# PIC32MK1024MCF064 device description
Architecture: MIPS; Family: PIC32MK; Series: PIC32MK
Registers are 32-bit, read-write, no defined reset value unless marked. A register's access mark holds for its fields unless they carry their own. Offsets are from the block's base; [hi:lo] are bit positions; lines under a group give offsets from that group; {n}, {i} and the like mark numbered series; 'fields as' and 'values as' point back to an identical list.

## RTCC
Instances: RTCC 0x1f8c0000 in periph_pb6_std
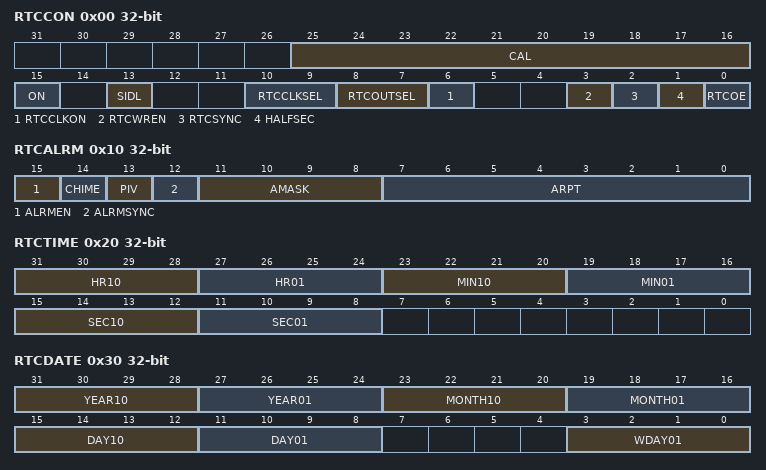
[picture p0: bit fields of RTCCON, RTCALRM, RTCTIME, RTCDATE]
0x00 RTCCON — Real-Time Clock and Calendar Control Register
  [25:16] CAL — Real-Time Clock Drift Calibration bits
    0x1ff=Maximum positive adjustment; 1=Minimum positive adjustment; 0=No adjustment; 0x3ff=Minimum negative adjustment; 0x200=Minimum negative adjustment
  [15] ON — RTCC On bit
    1=RTCC module is enabled; 0=RTCC module is disabled
  [13] SIDL — Stop in Idle Mode bit
    1=Disables RTCC operation when CPU enters Idle mode; 0=Continue normal operation when CPU enters Idle mode
  [10:9] RTCCLKSEL — RTCC Clock Select bits
    1=RTCC uses the external 32.768 kHz Secondary Oscillator (SOSC); 0=RTCC uses the internal 32 kHz oscillator (LPRC)
  [8:7] RTCOUTSEL — RTCC Output Data Select bits
    2=RTCC Clock is presented on the RTCC pin; 1=Seconds Clock is presented on the RTCC pin; 0=Alarm Pulse is presented on the RTCC pin when the alarm interrupt is triggered
  [6] RTCCLKON — RTCC Clock Enable Status bit
    1=RTCC Clock is actively running; 0=RTCC Clock is not running
  [3] RTCWREN — Real-Time Clock Value Registers Write Enable bit
    1=Real-Time Clock Value registers can be written to by the user; 0=Real-Time Clock Value registers are locked out from being written to by the user
  [2] RTCSYNC — Real-Time Clock Value Registers Read Synchronization bit
    1=Real-time clock value registers can change while reading (due to a rollover ripple that results in an invalid data read). If the register is read twice and results in the same data; 0=Real-time clock value registers can be read without concern about a rollover ripple
  [1] HALFSEC — Half-Second Status bit
    1=Second half period of a second; 0=First half period of a second
  [0] RTCOE — RTCC Output Enable bit
    1=RTCC output is enabled; 0=RTCC output is not enabled
0x10 RTCALRM — Real-Time Clock ALARM Control Register
  [15] ALRMEN — Alarm Enable bit
    1=Alarm is enabled; 0=Alarm is disabled
  [14] CHIME — Chime Enable bit
    1=Chime is enabled ARPT is allowed to rollover from 0x00 to 0xFF; 0=Chime is disabled ARPT stops once it reaches 0x00
  [13] PIV — Alarm Pulse Initial Value bit
    0=low initial value of the Alarm Pulse (When ALRMEN = 0); 1=high initial value of the Alarm Pulse (When ALRMEN = 0)
  [12] ALRMSYNC — Alarm Sync bit
    1=ARPT and ALRMEN may change as a result of a half second rollover during a read. The ARPT must be read repeatedly until the same value is read twice. This must be done since multiple bits may be changing.; 0=ARPT and ALRMEN can be read without concerns of rollover because the prescaler is more than 32 real-time clocks away from a half-second rollover
  [11:8] AMASK — Alarm Mask Configuration bits
    0=Every half-second; 1=Every second; 2=Every 10 seconds; 3=Every minute; 4=Every 10 minutes; 5=Every hour; 6=Once a day; 7=Once a week; 8=Once a month; 9=Once a year (except when configured for February 29
  [7:0] ARPT — Alarm Repeat Counter Value bits
    255=Alarm will trigger 256 times; 254=Alarm will trigger 255 times; 1=Alarm will trigger two times; 0=Alarm will trigger one time
0x20 RTCTIME — Real-Time Clock Time Value Register
  [31:28] HR10, [27:24] HR01, [23:20] MIN10, [19:16] MIN01, [15:12] SEC10, [11:8] SEC01
0x30 RTCDATE — Real-Time Clock Date Value Register
  [31:28] YEAR10, [27:24] YEAR01, [23:20] MONTH10, [19:16] MONTH01, [15:12] DAY10, [11:8] DAY01, [3:0] WDAY01
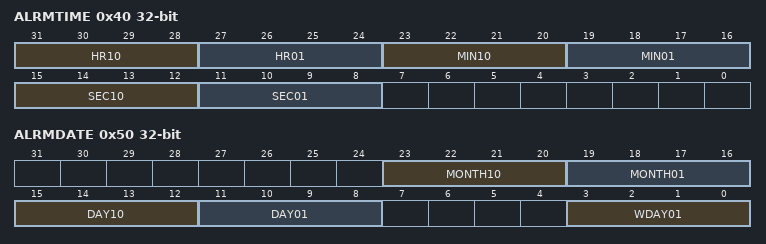
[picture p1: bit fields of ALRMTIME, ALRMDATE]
0x40 ALRMTIME — Alarm Time Value Register
  fields as RTCTIME
0x50 ALRMDATE — Alarm Date Value Register
  [23:20] MONTH10, [19:16] MONTH01, [15:12] DAY10, [11:8] DAY01, [3:0] WDAY01

## SB
Instances: SB 0x1f8f0510 in periph_ssx
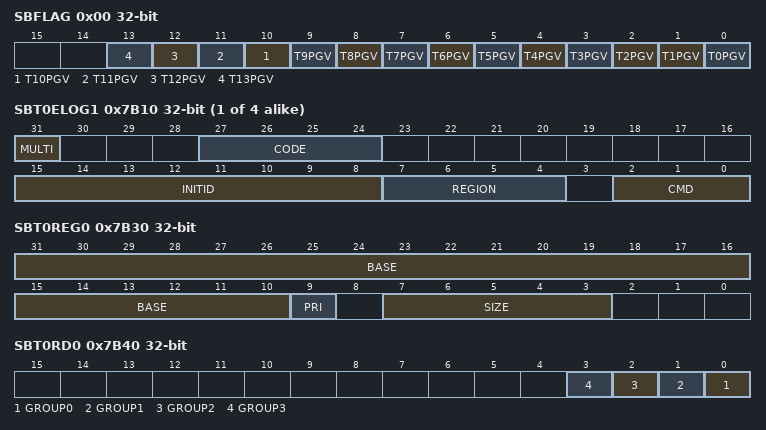
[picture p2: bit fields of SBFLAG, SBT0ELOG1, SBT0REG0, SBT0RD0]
0x00 SBFLAG ro — System Bus Status Flag Register
  [all] fields
    1=Target is reporting a Permission Group (PG) violation; 0=Target is not reporting a PG violation
  [n] T{n}PGV (n=2..13) — Target {n} Permission Group Violation Status bits
  [1] T1PGV — Target 1Permission Group Violation Status bits
  [0] T0PGV — Target 0 Permission Group Violation Status bits
{0x7B10+0x400*i} SBT{i}ELOG1 ro (i=0..3) — System Bus Target 'x' Error Log Register 1
  [31] MULTI — Multiple Permission Violations Status bit
    1=Multiple errors have been detected; 0=No multiple errors have been detected
  [27:24] CODE — Error Code bits
    3=Permission violation; 0=No error
  [15:8] INITID — Initiator ID of Requester bits
    14=Crypto Engine; 13=Flash Controller; 12=SQI1; 11=CAN2; 10=CAN1; 9=Ethernet Write; 8=Ethernet Read; 7=USB; 6=DMA Write (DMAPRI (CFGCON) = 1); 5=DMA Write (DMAPRI (CFGCON) = 0); 4=DMA Read (DMAPRI (CFGCON) = 1); 3=DMA Read (DMAPRI (CFGCON) = 0); 2=CPU (CPUPRI (CFGCON) = 1); 1=CPU (CPUPRI (CFGCON) = 0)
  [7:4] REGION — Requested Region Number bits
    1111 - 0000=Targets region that reported a permission group violation
  [2:0] CMD — Transaction Command of the Requester bits
    5=Write (a non-posted write); 3=Read (a locked read caused by a Read-Modify-Write transaction); 2=Read; 1=Write; 0=Idle
{0x7B14+0x400*i} SBT{i}ELOG2 ro (i=0..3) — System Bus Target 'x' Error Log Register 2
  [1:0] GROUP — Requested Permissions Group bits
    {v}=Group {v} (v=0..3)
{0x7B18+0x400*i} SBT{i}ECON (i=0..3) — System Bus Target 'x' Error Control Register
  [24] ERRP — Error Control bit
    1=Report protection group violation errors; 0=Do not report protection group violation errors
{0x7B20+0x400*i} SBT{i}ECLRS ro (i=0..3) — System Bus Target 'x' Single Error Clear Register
  [0] CLEAR
{0x7B28+0x400*i} SBT{i}ECLRM ro (i=0..3) — System Bus Target 'x' Multiple Error Clear Register
  [0] CLEAR
0x7B30 SBT0REG0
  [31:10] BASE
  [9] PRI — Region Priority Level bit
    1=Level 2; 0=Level 1
  [7:3] SIZE — Region Size bits
    0=Region is not present; 1=Region is 1024 bytes; 2=Region is 2048 bytes; 3=Region is 4096 bytes
0x7B40 SBT0RD0
  [n] GROUP{n} (n=0..3) — Group{n} Read Permissions bits
    1=Privilege Group {n} has read permission; 0=Privilege Group {n} does not have read permission
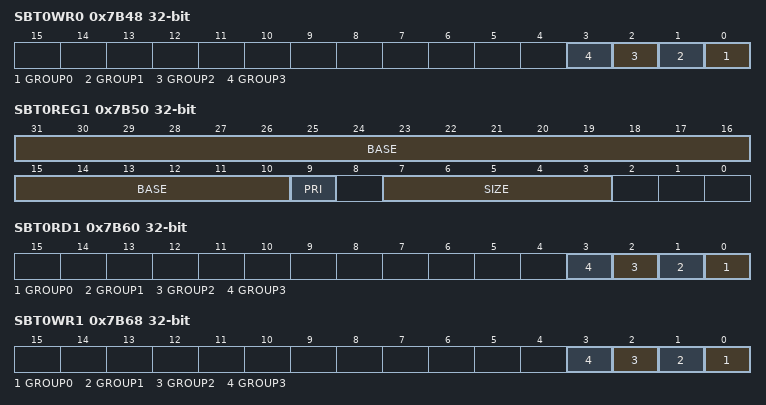
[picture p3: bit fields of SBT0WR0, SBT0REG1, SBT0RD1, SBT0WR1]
0x7B48 SBT0WR0
  [n] GROUP{n} (n=0..3) — Group {n} Write Permissions bits
    1=Privilege Group {n} has write permission; 0=Privilege Group {n} does not have write permission
0x7B50 SBT0REG1
  fields as SBT0REG0
0x7B60 SBT0RD1
  fields as SBT0RD0
0x7B68 SBT0WR1
  fields as SBT0WR0
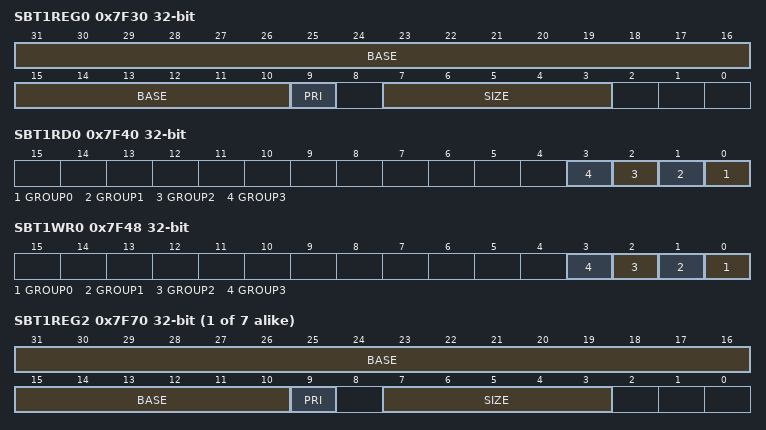
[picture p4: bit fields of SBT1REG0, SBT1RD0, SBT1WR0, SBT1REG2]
0x7F30 SBT1REG0
  fields as SBT0REG0
0x7F40 SBT1RD0
  fields as SBT0RD0
0x7F48 SBT1WR0
  fields as SBT0WR0
{0x7F30+0x20*i} SBT1REG{i} (i=2..8)
  fields as SBT0REG0
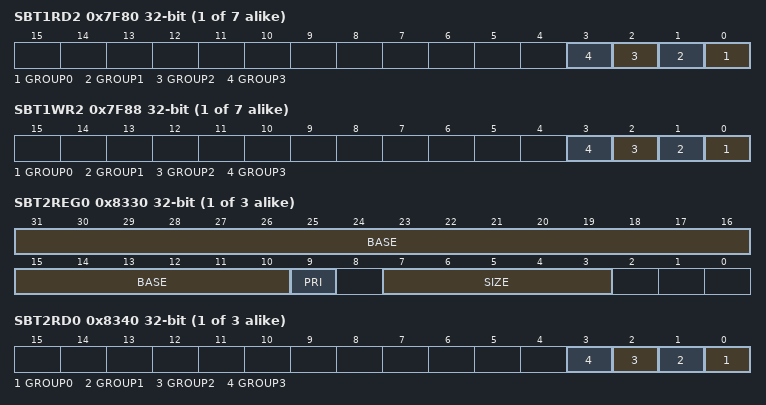
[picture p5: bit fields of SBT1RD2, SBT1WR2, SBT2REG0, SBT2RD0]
{0x7F40+0x20*i} SBT1RD{i} (i=2..8)
  fields as SBT0RD0
{0x7F48+0x20*i} SBT1WR{i} (i=2..8)
  fields as SBT0WR0
{0x8330+0x20*i} SBT2REG{i} (i=0..2)
  fields as SBT0REG0
{0x8340+0x20*i} SBT2RD{i} (i=0..2)
  fields as SBT0RD0
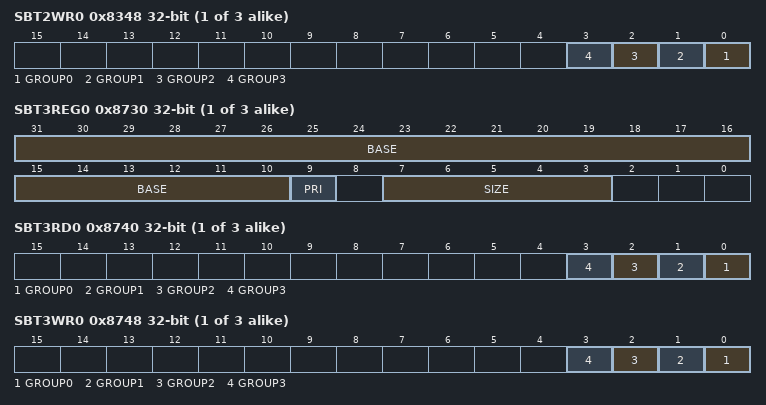
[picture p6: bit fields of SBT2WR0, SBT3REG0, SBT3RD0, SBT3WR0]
{0x8348+0x20*i} SBT2WR{i} (i=0..2)
  fields as SBT0WR0
{0x8730+0x20*i} SBT3REG{i} (i=0..2)
  fields as SBT0REG0
{0x8740+0x20*i} SBT3RD{i} (i=0..2)
  fields as SBT0RD0
{0x8748+0x20*i} SBT3WR{i} (i=0..2)
  fields as SBT0WR0
